VERSION ""

NS_ :

BS_:

BU_: BMS Out Dashboard PedalBoard IMU VCU

BO_ 3221225472 VECTOR__INDEPENDENT_SIG_MSG: 0 Vector__XXX
 SG_ motor2_current : 0|8@1- (1,0) [-128|127] "" Vector__XXX
 SG_ motor1_current : 0|8@1- (1,0) [-128|127] "" Vector__XXX

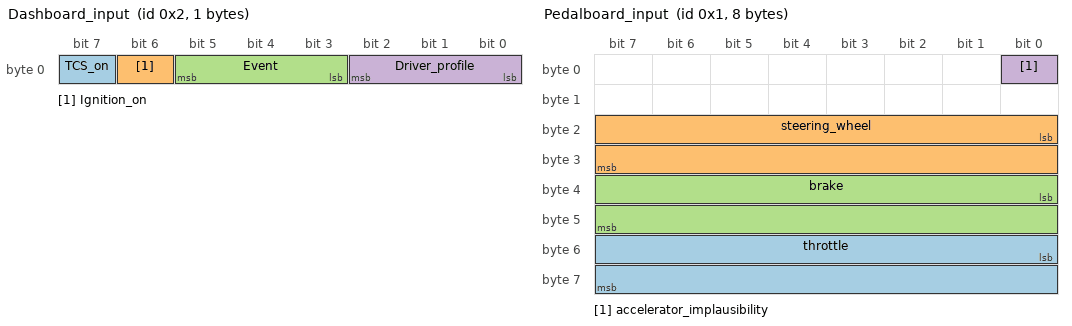
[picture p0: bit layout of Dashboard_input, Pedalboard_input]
BO_ 2 Dashboard_input: 1 Vector__XXX
 SG_ TCS_on : 7|1@1- (1,1) [0|1] "" Vector__XXX
 SG_ Ignition_on : 6|1@1- (1,1) [0|1] "" Vector__XXX
 SG_ Event : 3|3@1- (1,4) [0|7] "" Vector__XXX
 SG_ Driver_profile : 0|3@1- (1,4) [0|7] "" Vector__XXX

BO_ 1 Pedalboard_input: 8 PedalBoard
 SG_ throttle : 48|16@1+ (0.001526,0) [0|100.00641] "" Vector__XXX
 SG_ steering_wheel : 16|16@1- (0.001526,0) [-50.003968|50.002442] "" Vector__XXX
 SG_ brake : 32|16@1+ (0.001526,0) [0|100.00641] "" Vector__XXX
 SG_ accelerator_implausibility : 0|1@1+ (1,0) [0|1] "" Vector__XXX

BO_ 0 Display_info: 2 VCU
 SG_ car_speed : 0|16@1- (0.0035,80) [-34.688|194.6845] "" Vector__XXX

CM_ BO_ 3221225472 "This is a message for not used signals, created by Vector CANdb++ DBC OLE DB Provider.";
CM_ SG_ 3221225472 motor2_current "is it on CAN bus? check values";
CM_ SG_ 3221225472 motor1_current "is it on CAN bus? check values";
